# PIC18LF1330 register map
Vendor: Microchip
Registers are 8-bit, read-write, reset 0x0 unless marked. A register's access mark holds for its fields unless they carry their own. Addresses are absolute, and some are shared; only a register's first bit layout is shown; [hi:lo] are bit positions.

## CONFIG — Configuration words, addresses in ProgramSpace
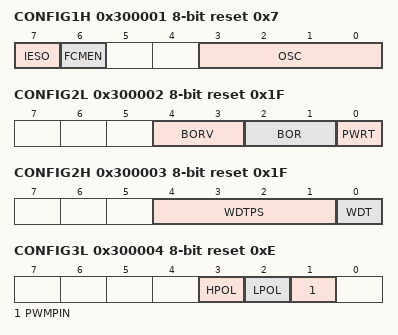
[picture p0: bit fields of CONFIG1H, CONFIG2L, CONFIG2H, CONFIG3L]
0x300001 CONFIG1H reset 0x7
  [7] IESO — Internal/External Oscillator Switchover bit
    1=ON (Oscillator Switchover mode enabled); 0=OFF (Oscillator Switchover mode disabled)
  [6] FCMEN — Fail-Safe Clock Monitor Enable bit
    1=ON (Fail-Safe Clock Monitor enabled); 0=OFF (Fail-Safe Clock Monitor disabled)
  [3:0] OSC — Oscillator
    0b11xx=11XX External RC oscillator, CLKO function on RA6; 0b101x=101X External RC oscillator, CLKO function on RA6; 9=INTIO1 (Internal oscillator, CLKO function on RA6, port function on RA7); 8=INTIO2 (Internal oscillator, port function on RA6 and RA7); 7=RCIO (External RC oscillator, port function on RA6); 6=HSPLL (HS oscillator, PLL enabled (Clock Frequency = 4 x FOSC1)); 5=ECIO (EC oscillator, port function on RA6); 4=EC (EC oscillator, CLKO function on RA6); 3=RC (External RC oscillator, CLKO function on RA6); 2=HS (HS Oscillator); 1=XT (XT Oscillator); 0=LP (LP Oscillator)
0x300002 CONFIG2L reset 0x1F
  [4:3] BORV — Brown-out Reset Voltage bits
    3=Minimum setting; 2=2; 1=1; 0=Maximum setting
  [2:1] BOR — Brown-out Reset Enable bits
    3=BOHW (Brown-out Reset enabled in hardware only (SBOREN is disabled)); 2=BOACTIVE (Brown-out Reset enabled in hardware only and disabled in Sleep mode (SBOREN is disabled)); 1=SBORENCTRL (Brown-out Reset enabled and controlled by software (SBOREN is enabled)); 0=OFF (Brown-out Reset disabled in hardware and software)
  [0] PWRT — Power-up Timer Enable bit
    1=OFF (PWRT disabled); 0=ON (PWRT enabled)
0x300003 CONFIG2H reset 0x1F
  [4:1] WDTPS — Watchdog Timer Postscale Select bits
    15=1:32768; 14=1:16384; 13=1:8192; 12=1:4096; 11=1:2048; 10=1:1024; 9=1:512; 8=1:256; 7=1:128; 6=1:64; 5=1:32; 4=1:16; 3=1:8; 2=1:4; 1=1:2; 0=1:1
  [0] WDT — Watchdog Timer Enable bit
    1=ON (WDT enabled); 0=OFF (WDT disabled (control is placed on the SWDTEN bit))
0x300004 CONFIG3L reset 0xE
  [3] HPOL — High Side Transistors Polarity bit (Odd PWM Output Polarity Control bit)
    1=HIGH (PWM1, PWM3 and PWM5 are active-high (default)); 0=LOW (PWM1, PWM3 and PWM5 are active-low)
  [2] LPOL — Low-Side Transistors Polarity bit (Even PWM Output Polarity Control bit)
    1=HIGH (PWM0, PWM2 and PWM4 are active-high (default)); 0=LOW (PWM0, PWM2 and PWM4 are active-low)
  [1] PWMPIN — PWM Output Pins Reset State Control bit
    1=OFF (PWM outputs disabled upon Reset); 0=ON (PWM outputs drive active states upon Reset)
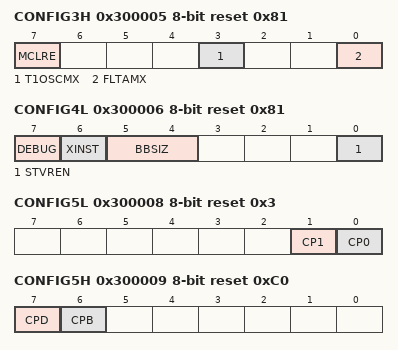
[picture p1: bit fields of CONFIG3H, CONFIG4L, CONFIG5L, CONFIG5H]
0x300005 CONFIG3H reset 0x81
  [7] MCLRE — Master Clear Enable bit
    1=ON (MCLR pin enabled, RA5 input pin disabled); 0=OFF (RA5 input pin enabled, MCLR pin disabled)
  [3] T1OSCMX — T1OSO/T1CKI MUX bit
    1=HIGH (T1OSO/T1CKI pin resides on RA6); 0=LOW (T1OSO/T1CKI pin resides on RB2)
  [0] FLTAMX — FLTA Mux bit
    1=RA5 (FLTA input is muxed onto RA5); 0=RA7 (FLTA input is muxed onto RA7)
0x300006 CONFIG4L reset 0x81
  [7] DEBUG — Background Debugger Enable bit
    1=OFF (Background debugger disabled, RB6 and RB7 configured as general purpose I/O pins); 0=ON (Background debugger enabled, RB6 and RB7 are dedicated to In-Circuit Debug)
  [6] XINST — Extended Instruction Set Enable bit
    1=ON (Instruction set extension and Indexed Addressing mode enabled); 0=OFF (Instruction set extension and Indexed Addressing mode disabled)
  [5:4] BBSIZ — Boot Block Size Select bits
    3=BB1K (1K Words (2048 Bytes) Boot Block size); 2=1K Words (2048 Bytes) Boot Block size; 1=BB512 (512 Words (1024 Bytes) Boot Block size); 0=BB256 (256 Words (512 Bytes) Boot Block size)
  [0] STVREN — Stack Overflow/Underflow Reset Enable bit
    1=ON (Reset on stack overflow/underflow enabled); 0=OFF (Reset on stack overflow/underflow disabled)
0x300008 CONFIG5L reset 0x3
  [1] CP1 — Code Protection bit Block 1 (001000-001FFF)
    1=OFF (Block 1 is not code-protected); 0=ON (Block 1 is code-protected)
  [0] CP0 — Code Protection bit Block 0 (000800-000FFF)
    1=OFF (Block 0 is not code-protected); 0=ON (Block 0 is code-protected)
0x300009 CONFIG5H reset 0xC0
  [7] CPD — Code Protection bit (Data EEPROM)
    1=OFF (Data EEPROM is not code-protected); 0=ON (Data EEPROM is code-protected)
  [6] CPB — Code Protection bit (Boot Block Memory Area)
    1=OFF (Boot Block is not code-protected); 0=ON (Boot Block is code-protected)
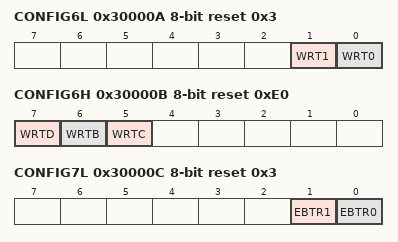
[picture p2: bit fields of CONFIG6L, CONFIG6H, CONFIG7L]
0x30000A CONFIG6L reset 0x3
  [1] WRT1 — Write Protection bit Block 1 (001000-001FFF)
    1=OFF (Block 1 is not write-protected); 0=ON (Block 1 is write-protected)
  [0] WRT0 — Write Protection bit Block 0 (000800-000FFF)
    1=OFF (Block 0 is not write-protected); 0=ON (Block 0 is write-protected)
0x30000B CONFIG6H reset 0xE0
  [7] WRTD — Write Protection bit (Data EEPROM)
    1=OFF (Data EEPROM is not write-protected); 0=ON (Data EEPROM is write-protected)
  [6] WRTB — Write Protection bit (Boot Block Memory Area)
    1=OFF (Boot Block is not write-protected); 0=ON (Boot Block is write-protected)
  [5] WRTC — Write Protection bit (Configuration Registers)
    1=OFF (Configuration registers are not write-protected); 0=ON (Configuration registers are write-protected)
0x30000C CONFIG7L reset 0x3
  [1] EBTR1 — Table Read Protection bit Block 1 (001000-001FFF)
    1=OFF (Block 1 is not protected from table reads executed in other blocks); 0=ON (Block 1 is protected from table reads executed in other blocks)
  [0] EBTR0 — Table Read Protection bit Block 0 (000800-000FFF)
    1=OFF (Block 0 is not protected from table reads executed in other blocks); 0=ON (Block 0 is protected from table reads executed in other blocks)
0x30000D CONFIG7H reset 0x40
  [6] EBTRB — Table Read Protection bit (Boot Block Memory Area)
    1=OFF (Boot Block is not protected from table reads executed in other blocks); 0=ON (Boot Block is protected from table reads executed in other blocks)
